AUTOSAR XML (schema 00048)
package /ComponentTypes
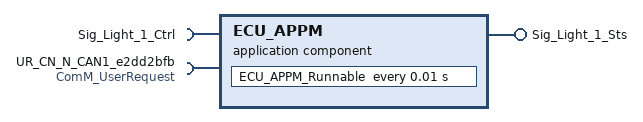
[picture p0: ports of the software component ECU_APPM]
  application sw component type ECU_APPM
    require port Sig_Light_1_Ctrl: nonqueued-receiver-com-spec{data-element=Sig_Light_1_Ctrl, init-value=0}, required-interface=Sig_Light_1_Ctrl
    provide port Sig_Light_1_Sts: nonqueued-sender-com-spec{data-element=Sig_Light_1_Sts, init-value=0}, provided-interface=Sig_Light_1_Sts
    require port UR_CN_N_CAN1_e2dd2bfb: required-com-specs=[RequestComMode, GetCurrentComMode, GetMaxComMode, GetRequestedComMode], required-interface=ComM_UserRequest
    behavior ECU_APPM_InternalBehavior
      timing event TMT_ECU_APPM_Runnable: start-on-event=ECU_APPM_Runnable, period=0.01
      runnable ECU_APPM_Runnable
        data-receive-point-by-arguments:
          access REC_Sig_Light_1_Ctrl_Sig_Light_1_Ctrl: accessed-variable=Sig_Light_1_Ctrl.Sig_Light_1_Ctrl
        data-send-points:
          access SEND_Sig_Light_1_Sts_Sig_Light_1_Sts: accessed-variable=Sig_Light_1_Sts.Sig_Light_1_Sts
        4 x sync call:
          SC_UR_CN_N_CAN1_e2dd2bfb_GetCurrentComMode: operation=UR_CN_N_CAN1_e2dd2bfb.GetCurrentComMode
          SC_UR_CN_N_CAN1_e2dd2bfb_GetMaxComMode: operation=UR_CN_N_CAN1_e2dd2bfb.GetMaxComMode
          SC_UR_CN_N_CAN1_e2dd2bfb_GetRequestedComMode: operation=UR_CN_N_CAN1_e2dd2bfb.GetRequestedComMode
          SC_UR_CN_N_CAN1_e2dd2bfb_RequestComMode: operation=UR_CN_N_CAN1_e2dd2bfb.RequestComMode
  swc implementation ECU_APPM_Implementation: behavior=ECU_APPM_InternalBehavior
